# CY8C5568AXI_060 register map
File version: 0.1
CY8C55
Registers are 8-bit, read-write, no defined reset value unless marked. A register's access mark holds for its fields unless they carry their own. Offsets are from the block's base; lines under a group give offsets from that group; [hi:lo] are bit positions; {n}, {i} and the like mark numbered series; 'fields as' and 'values as' point back to an identical list; <NAME> marks a mode.

## Memory map
0x400043A3 Counter_1 size 0xB62
0x400043AA ADC_DelSig_V size 0x17E0
0x40006407 SPIS_1 size 0x66
0x4000642E UART_1 size 0x40 — UART
0x40006476 PWM_BUCK size 0x122
0x40006577 Control_Reg_1 size 0x1

## SPIS_1
Base 0x40006407
0x00 SPIS_1_RX_DATA — SPIS RX Data
0x01 SPIS_1_TX_DATA — SPIS TX Data
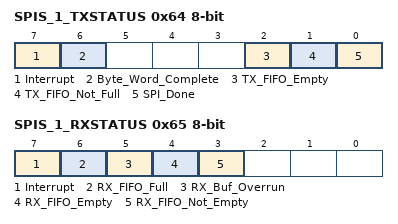
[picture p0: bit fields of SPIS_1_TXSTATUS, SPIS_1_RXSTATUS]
0x64 SPIS_1_TXSTATUS — SPIS TX Status Register
  [7] Interrupt ro — Set when interrupt occurs
  [6] Byte_Word_Complete ro — Set when a byte/word transmit has completed
  [2] TX_FIFO_Empty ro — Set when the TX Data FIFO is empty
  [1] TX_FIFO_Not_Full ro — Set when the TX Data FIFO is not full
  [0] SPI_Done ro — Set when all of the data in the transmit FIFO has been sent. Set when Byte/Word Complete has been set and TX Data FIFO is empty
0x65 SPIS_1_RXSTATUS — SPIS RX Status Register
  [7] Interrupt ro — Set when interrupt occurs
  [6] RX_FIFO_Full ro — Set when the RX Data FIFO is full
  [5] RX_Buf_Overrun ro — Set when RX Data has overrun the 4 byte/word FIFO without being moved to the RX buffer memory array (if one exists)
  [4] RX_FIFO_Empty ro — Set when the RX Data FIFO is empty
  [3] RX_FIFO_Not_Empty ro — Set when the RX Data FIFO is not empty. That is, at least one byte/word is in the RX FIFO (does not indicate the RX buffer RAM array conditions)

## UART_1 — UART
Base 0x4000642E
0x00 RX_UART_1_RX_ADDRESS1 — RX Address1 Register
0x10 RX_UART_1_RX_ADDRESS2 — RX Address2 Register
0x1C TX_UART_1_TX_DATA — TX Data Register
0x20 RX_UART_1_RX_DATA — RX Data Register
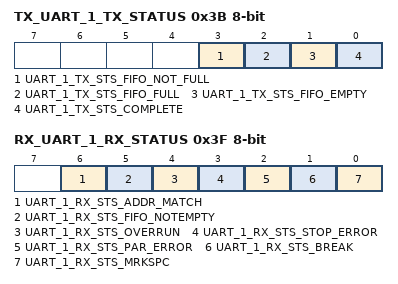
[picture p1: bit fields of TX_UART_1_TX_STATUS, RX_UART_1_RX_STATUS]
0x3B TX_UART_1_TX_STATUS — TX status register
  [3] UART_1_TX_STS_FIFO_NOT_FULL ro, [2] UART_1_TX_STS_FIFO_FULL ro, [1] UART_1_TX_STS_FIFO_EMPTY ro, [0] UART_1_TX_STS_COMPLETE ro
0x3F RX_UART_1_RX_STATUS — RX status register
  [6] UART_1_RX_STS_ADDR_MATCH ro, [5] UART_1_RX_STS_FIFO_NOTEMPTY ro, [4] UART_1_RX_STS_OVERRUN ro, [3] UART_1_RX_STS_STOP_ERROR ro, [2] UART_1_RX_STS_PAR_ERROR ro, [1] UART_1_RX_STS_BREAK ro, [0] UART_1_RX_STS_MRKSPC ro

## Counter_1
Base 0x400043A3
0x00 Counter_1_GLOBAL_ENABLE — PM.ACT.CFG
  [3:0] en_timer — Enable timer/counters.
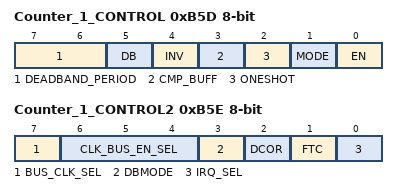
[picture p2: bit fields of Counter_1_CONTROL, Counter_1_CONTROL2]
0xB5D Counter_1_CONTROL — TMRx.CFG0
  [7:6] DEADBAND_PERIOD
  [5] DB — Deadband mode--Deadband phases phi1 and phi2 are outputted on CMP and TC output pins respectively.
    0=Timer (CMP and TC are output.); 1=Deadband (PHI1 (instead of CMP) and PHI2 (instead of TC) are output.)
  [4] INV — Invert sense of TIMEREN signal
  [3] CMP_BUFF — Buffer compare register. Compare register updates only on timer terminal count.
  [2] ONESHOT — Timer stops upon reaching stop condition defined by TMR_CFG bits. Can be restarted by asserting TIMER RESET or disabling and re-enabling block.
  [1] MODE — Mode. (0 = Timer; 1 = Comparator)
    0=Timer mode. CNT/CMP register holds timer count value.; 1=Comparator mode. CNT/CMP register holds comparator threshold value.
  [0] EN — Enables timer/comparator.
0xB5E Counter_1_CONTROL2 — TMRx.CFG1
  [7] BUS_CLK_SEL — Bus Clock selection.
  [6:4] CLK_BUS_EN_SEL — Digital Global Clock selection.
  [3] DBMODE — Deadband mode (asynchronous/synchronous). CMP output pin is also affected when not in deadband mode (CFG0.DEADBAND).
  [2] DCOR — Disable Clear on Read (DCOR) of Status Register SR0.
  [1] FTC — First Terminal Count (FTC). Setting this bit forces a single pulse on the TC pin when first enabled.
    0=Disable_FTC (Disable the single cycle pulse, which signifies the timer is starting.); 1=Enable_FTC (Enable the single cycle pulse, which signifies the timer is starting.)
  [0] IRQ_SEL — Irq selection. (0 = raw interrupts; 1 = status register interrupts)
0xB5F Counter_1_PERIOD 16-bit — TMRx.PER0 - Assigned Period
0xB61 Counter_1_COUNTER 16-bit — TMRx.CNT_CMP0 - Current Down Counter Value
